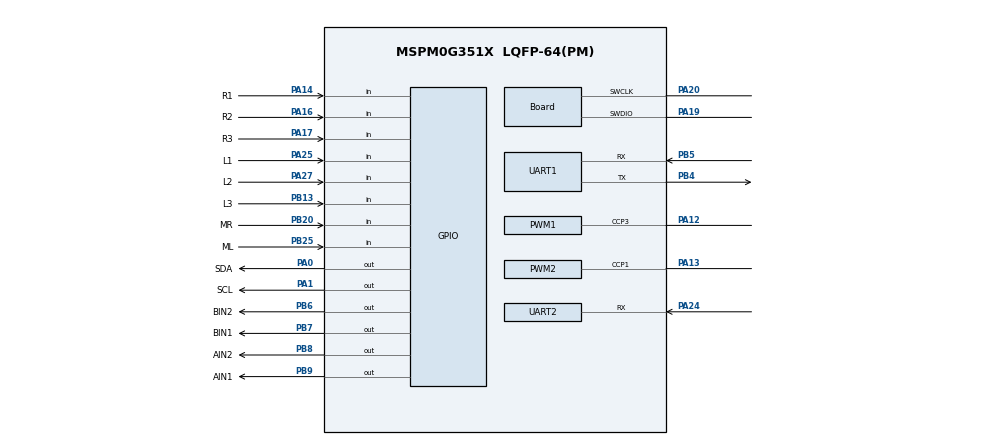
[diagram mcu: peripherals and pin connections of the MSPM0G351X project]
/**
 *
 * @cliArgs --device "MSPM0G351X" --part "Default" --package "LQFP-64(PM)" --product "mspm0_sdk@2.11.00.07"
 * @versions {"tool":"1.28.0+4712"}
 */

/**
 * Import the modules used in this configuration.
 */
const GPIO   = scripting.addModule("/ti/driverlib/GPIO", {}, false);
const GPIO1  = GPIO.addInstance();
const GPIO2  = GPIO.addInstance();
const GPIO3  = GPIO.addInstance();
const GPIO4  = GPIO.addInstance();
const PWM    = scripting.addModule("/ti/driverlib/PWM", {}, false);
const PWM1   = PWM.addInstance();
const PWM2   = PWM.addInstance();
const SYSCTL = scripting.addModule("/ti/driverlib/SYSCTL");
const TIMER  = scripting.addModule("/ti/driverlib/TIMER", {}, false);
const TIMER1 = TIMER.addInstance();
const UART   = scripting.addModule("/ti/driverlib/UART", {}, false);
const UART1  = UART.addInstance();
const UART2  = UART.addInstance();

/**
 * Write custom configuration values to the imported modules.
 */
const gate7  = system.clockTree["MFCLKGATE"];
gate7.enable = true;

GPIO1.$name                          = "OLED";
GPIO1.port                           = "PORTA";
GPIO1.associatedPins.create(2);
GPIO1.associatedPins[0].$name        = "SCL";
GPIO1.associatedPins[0].initialValue = "SET";
GPIO1.associatedPins[0].ioStructure  = "OD";
GPIO1.associatedPins[0].assignedPin  = "1";
GPIO1.associatedPins[0].pin.$assign  = "PA1";
GPIO1.associatedPins[1].$name        = "SDA";
GPIO1.associatedPins[1].initialValue = "SET";
GPIO1.associatedPins[1].ioStructure  = "OD";
GPIO1.associatedPins[1].assignedPin  = "0";
GPIO1.associatedPins[1].pin.$assign  = "PA0";

const Board                       = scripting.addModule("/ti/driverlib/Board", {}, false);
Board.peripheral.$assign          = "DEBUGSS";
Board.peripheral.swclkPin.$assign = "PA20";
Board.peripheral.swdioPin.$assign = "PA19";

GPIO2.$name                              = "TB";
GPIO2.associatedPins.create(8);
GPIO2.associatedPins[0].$name            = "AIN1";
GPIO2.associatedPins[0].assignedPin      = "9";
GPIO2.associatedPins[0].assignedPort     = "PORTB";
GPIO2.associatedPins[0].pin.$assign      = "PB9";
GPIO2.associatedPins[1].$name            = "AIN2";
GPIO2.associatedPins[1].assignedPort     = "PORTB";
GPIO2.associatedPins[1].assignedPin      = "8";
GPIO2.associatedPins[1].pin.$assign      = "PB8";
GPIO2.associatedPins[2].$name            = "BIN1";
GPIO2.associatedPins[2].assignedPort     = "PORTB";
GPIO2.associatedPins[2].assignedPin      = "7";
GPIO2.associatedPins[2].pin.$assign      = "PB7";
GPIO2.associatedPins[3].$name            = "BIN2";
GPIO2.associatedPins[3].assignedPort     = "PORTB";
GPIO2.associatedPins[3].assignedPin      = "6";
GPIO2.associatedPins[3].pin.$assign      = "PB6";
GPIO2.associatedPins[4].$name            = "E2A";
GPIO2.associatedPins[4].assignedPort     = "PORTB";
GPIO2.associatedPins[4].assignedPin      = "15";
GPIO2.associatedPins[4].direction        = "INPUT";
GPIO2.associatedPins[4].interruptEn      = true;
GPIO2.associatedPins[4].polarity         = "RISE";
GPIO2.associatedPins[4].internalResistor = "PULL_DOWN";
GPIO2.associatedPins[5].$name            = "E2B";
GPIO2.associatedPins[5].assignedPort     = "PORTB";
GPIO2.associatedPins[5].assignedPin      = "16";
GPIO2.associatedPins[5].direction        = "INPUT";
GPIO2.associatedPins[6].$name            = "E1A";
GPIO2.associatedPins[6].direction        = "INPUT";
GPIO2.associatedPins[6].internalResistor = "PULL_DOWN";
GPIO2.associatedPins[6].interruptEn      = true;
GPIO2.associatedPins[6].assignedPort     = "PORTB";
GPIO2.associatedPins[6].assignedPin      = "10";
GPIO2.associatedPins[6].polarity         = "RISE";
GPIO2.associatedPins[7].assignedPort     = "PORTB";
GPIO2.associatedPins[7].assignedPin      = "11";
GPIO2.associatedPins[7].$name            = "E1B";
GPIO2.associatedPins[7].direction        = "INPUT";

GPIO3.$name                              = "GRAY";
GPIO3.associatedPins.create(8);
GPIO3.associatedPins[0].$name            = "L3";
GPIO3.associatedPins[0].direction        = "INPUT";
GPIO3.associatedPins[0].internalResistor = "PULL_DOWN";
GPIO3.associatedPins[0].pin.$assign      = "PB13";
GPIO3.associatedPins[1].$name            = "L2";
GPIO3.associatedPins[1].direction        = "INPUT";
GPIO3.associatedPins[1].internalResistor = "PULL_DOWN";
GPIO3.associatedPins[1].assignedPort     = "PORTA";
GPIO3.associatedPins[1].assignedPin      = "27";
GPIO3.associatedPins[1].pin.$assign      = "PA27";
GPIO3.associatedPins[2].$name            = "L1";
GPIO3.associatedPins[2].direction        = "INPUT";
GPIO3.associatedPins[2].internalResistor = "PULL_DOWN";
GPIO3.associatedPins[2].assignedPin      = "25";
GPIO3.associatedPins[2].assignedPort     = "PORTA";
GPIO3.associatedPins[2].pin.$assign      = "PA25";
GPIO3.associatedPins[3].$name            = "ML";
GPIO3.associatedPins[3].direction        = "INPUT";
GPIO3.associatedPins[3].internalResistor = "PULL_DOWN";
GPIO3.associatedPins[3].assignedPort     = "PORTB";
GPIO3.associatedPins[3].assignedPin      = "25";
GPIO3.associatedPins[3].pin.$assign      = "PB25";
GPIO3.associatedPins[4].$name            = "MR";
GPIO3.associatedPins[4].direction        = "INPUT";
GPIO3.associatedPins[4].internalResistor = "PULL_DOWN";
GPIO3.associatedPins[4].assignedPort     = "PORTB";
GPIO3.associatedPins[4].assignedPin      = "20";
GPIO3.associatedPins[4].pin.$assign      = "PB20";
GPIO3.associatedPins[5].$name            = "R1";
GPIO3.associatedPins[5].direction        = "INPUT";
GPIO3.associatedPins[5].internalResistor = "PULL_DOWN";
GPIO3.associatedPins[5].assignedPort     = "PORTA";
GPIO3.associatedPins[5].assignedPin      = "14";
GPIO3.associatedPins[5].pin.$assign      = "PA14";
GPIO3.associatedPins[6].$name            = "R2";
GPIO3.associatedPins[6].direction        = "INPUT";
GPIO3.associatedPins[6].internalResistor = "PULL_DOWN";
GPIO3.associatedPins[6].assignedPort     = "PORTA";
GPIO3.associatedPins[6].assignedPin      = "16";
GPIO3.associatedPins[6].pin.$assign      = "PA16";
GPIO3.associatedPins[7].$name            = "R3";
GPIO3.associatedPins[7].direction        = "INPUT";
GPIO3.associatedPins[7].internalResistor = "PULL_DOWN";
GPIO3.associatedPins[7].pin.$assign      = "PA17";

GPIO4.$name                              = "LED1";
GPIO4.associatedPins[0].$name            = "PIN_22";
GPIO4.associatedPins[0].assignedPin      = "22";
GPIO4.associatedPins[0].assignedPort     = "PORTB";
GPIO4.associatedPins[0].internalResistor = "PULL_DOWN";

PWM1.$name                      = "PWMA";
PWM1.clockDivider               = 8;
PWM1.ccIndex                    = [3];
PWM1.peripheral.$assign         = "TIMA0";
PWM1.peripheral.ccp3Pin.$assign = "PA12";
PWM1.PWM_CHANNEL_3.$name        = "ti_driverlib_pwm_PWMTimerCC0";
PWM1.PWM_CHANNEL_3.ccValue      = 999;
PWM1.ccp3PinConfig.$name        = "ti_driverlib_gpio_GPIOPinGeneric0";

PWM2.clockDivider                       = 8;
PWM2.$name                              = "PWMB";
PWM2.ccIndex                            = [1];
PWM2.ccp1PinConfig.direction            = scripting.forceWrite("OUTPUT");
PWM2.ccp1PinConfig.hideOutputInversion  = scripting.forceWrite(false);
PWM2.ccp1PinConfig.onlyInternalResistor = scripting.forceWrite(false);
PWM2.ccp1PinConfig.passedPeripheralType = scripting.forceWrite("Digital");
PWM2.ccp1PinConfig.$name                = "ti_driverlib_gpio_GPIOPinGeneric1";
PWM2.peripheral.$assign                 = "TIMG0";
PWM2.peripheral.ccp1Pin.$assign         = "PA13";
PWM2.PWM_CHANNEL_1.$name                = "ti_driverlib_pwm_PWMTimerCC1";

SYSCTL.forceDefaultClkConfig = true;
SYSCTL.clockTreeEn           = true;

TIMER1.$name              = "TIMER_0";
TIMER1.timerPeriod        = "1 ms";
TIMER1.timerClkDiv        = 8;
TIMER1.timerStartTimer    = true;
TIMER1.timerClkPrescale   = 100;
TIMER1.timerMode          = "PERIODIC";
TIMER1.interrupts         = ["ZERO"];
TIMER1.peripheral.$assign = "TIMA1";

UART1.enableFIFO                        = true;
UART1.rxFifoThreshold                   = "DL_UART_RX_FIFO_LEVEL_ONE_ENTRY";
UART1.enableDMATX                       = false;
UART1.$name                             = "UART1";
UART1.enabledDMATXTriggers              = "DL_UART_DMA_INTERRUPT_TX";
UART1.enabledInterrupts                 = ["RX"];
UART1.interruptPriority                 = "1";
UART1.peripheral.$assign                = "UART1";
UART1.peripheral.rxPin.$assign          = "PB5";
UART1.peripheral.txPin.$assign          = "PB4";
UART1.txPinConfig.direction             = scripting.forceWrite("OUTPUT");
UART1.txPinConfig.hideOutputInversion   = scripting.forceWrite(false);
UART1.txPinConfig.onlyInternalResistor  = scripting.forceWrite(false);
UART1.txPinConfig.passedPeripheralType  = scripting.forceWrite("Digital");
UART1.txPinConfig.$name                 = "ti_driverlib_gpio_GPIOPinGeneric1_COPY";
UART1.rxPinConfig.hideOutputInversion   = scripting.forceWrite(false);
UART1.rxPinConfig.onlyInternalResistor  = scripting.forceWrite(false);
UART1.rxPinConfig.passedPeripheralType  = scripting.forceWrite("Digital");
UART1.rxPinConfig.$name                 = "ti_driverlib_gpio_GPIOPinGeneric2_COPY";
UART1.DMA_CHANNEL_TX.$name              = "DMA_TxBlue";
UART1.DMA_CHANNEL_TX.srcLength          = "BYTE";
UART1.DMA_CHANNEL_TX.dstLength          = "BYTE";
UART1.DMA_CHANNEL_TX.addressMode        = "b2f";
UART1.DMA_CHANNEL_TX.enableInterrupt    = true;
UART1.DMA_CHANNEL_TX.peripheral.$assign = "DMA_CH0";

UART2.rxFifoThreshold                   = "DL_UART_RX_FIFO_LEVEL_ONE_ENTRY";
UART2.enableDMATX                       = false;
UART2.direction                         = "RX";
UART2.enabledDMARXTriggers              = "DL_UART_DMA_INTERRUPT_RX";
UART2.targetBaudRate                    = 115200;
UART2.$name                             = "UART7";
UART2.enableFIFO                        = true;
UART2.rxPinConfig.hideOutputInversion   = scripting.forceWrite(false);
UART2.rxPinConfig.onlyInternalResistor  = scripting.forceWrite(false);
UART2.rxPinConfig.passedPeripheralType  = scripting.forceWrite("Digital");
UART2.rxPinConfig.$name                 = "ti_driverlib_gpio_GPIOPinGeneric2_COPY1";
UART2.peripheral.$assign                = "UART7";
UART2.peripheral.rxPin.$assign          = "PA24";
UART2.DMA_CHANNEL_RX.srcLength          = "BYTE";
UART2.DMA_CHANNEL_RX.dstLength          = "BYTE";
UART2.DMA_CHANNEL_RX.addressMode        = "f2b";
UART2.DMA_CHANNEL_RX.$name              = "DMA_RxJY_COPY";
UART2.DMA_CHANNEL_RX.enableInterrupt    = true;
UART2.DMA_CHANNEL_RX.transferMode       = "FULL_CH_REPEAT_SINGLE";
UART2.DMA_CHANNEL_RX.peripheral.$assign = "DMA_CH1";

const ProjectConfig              = scripting.addModule("/ti/project_config/ProjectConfig", {}, false);
ProjectConfig.migrationCondition = true;

/**
 * Pinmux solution for unlocked pins/peripherals. This ensures that minor changes to the automatic solver in a future
 * version of the tool will not impact the pinmux you originally saw.  These lines can be completely deleted in order to
 * re-solve from scratch.
 */
GPIO2.associatedPins[4].pin.$suggestSolution = "PB15";
GPIO2.associatedPins[5].pin.$suggestSolution = "PB16";
GPIO2.associatedPins[6].pin.$suggestSolution = "PB10";
GPIO2.associatedPins[7].pin.$suggestSolution = "PB11";
GPIO4.associatedPins[0].pin.$suggestSolution = "PB22";
